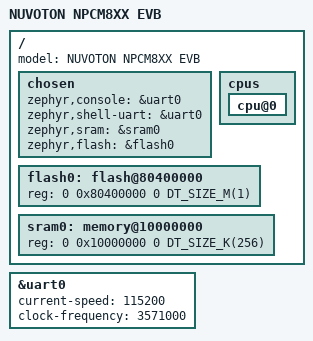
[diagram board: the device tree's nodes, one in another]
/*
 * Copyright 2023 Nuvoton
 *
 * SPDX-License-Identifier: Apache-2.0
 */

/dts-v1/;

#include <nuvoton/nuvoton-common-npcm8xx.dtsi>

/ {
	model = "NUVOTON NPCM8XX EVB";

	chosen {
		zephyr,console = &uart0;
		zephyr,shell-uart = &uart0;
		zephyr,sram = &sram0;
		zephyr,flash = &flash0;
	};

	cpus {
		cpu@0 {
			status = "okay";
		};
	};

	flash0: flash@80400000 {
		reg = <0 0x80400000 0 DT_SIZE_M(1)>;
	};

	sram0: memory@10000000   {
		reg = <0 0x10000000  0 DT_SIZE_K(256)>;
	};
};

&uart0 {
	current-speed = <115200>;
	clock-frequency = <3571000>;
	status = "okay";
};
